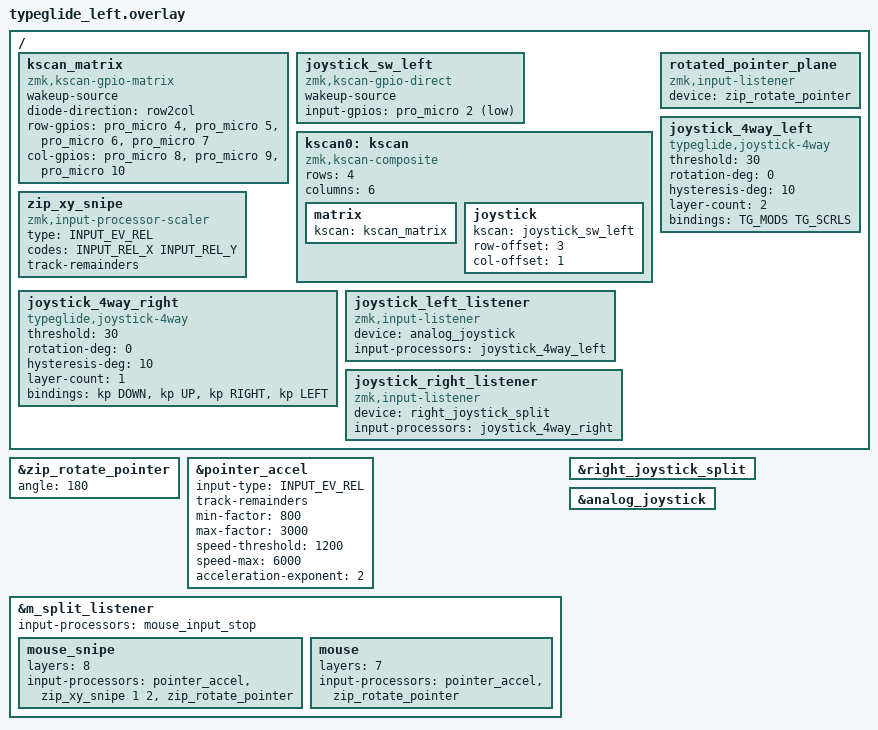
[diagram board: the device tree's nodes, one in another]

#include "typeglide.dtsi"
#include "joystick.dtsi"

#include <dt-bindings/gpio/gpio.h>
#include <input/processors/rotate_plane.dtsi>
#include <input_processor_stop.dtsi>
#include <behaviors/mouse_scroll.dtsi>
#include <dt-bindings/zmk/pointing.h>
#include <input/processors.dtsi>
#include <behaviors/input_gestures_accel.dtsi>
#include <keymap_defs.dtsi>

/*
 * Left half
 *
 * col 0 = ring (outermost)
 * col 1 = middle
 * col 2 = index (innermost)
 *
 * row 3 col 0 = pinky
 * row 3 col 2 = thumb
 * row 3 col 1 = spare
 */

 / {
    kscan_matrix: kscan_matrix {
        compatible = "zmk,kscan-gpio-matrix";
        wakeup-source;
        diode-direction = "row2col";

        row-gpios
            = <&pro_micro 4 GPIO_ACTIVE_HIGH>
            , <&pro_micro 5 GPIO_ACTIVE_HIGH>
            , <&pro_micro 6 GPIO_ACTIVE_HIGH>
            , <&pro_micro 7 GPIO_ACTIVE_HIGH>
            ;

        col-gpios
            = <&pro_micro 8  (GPIO_ACTIVE_HIGH | GPIO_PULL_DOWN)>
            , <&pro_micro 9  (GPIO_ACTIVE_HIGH | GPIO_PULL_DOWN)>
            , <&pro_micro 10 (GPIO_ACTIVE_HIGH | GPIO_PULL_DOWN)>
            ;
    };

    joystick_sw_left: joystick_sw_left {
            compatible = "zmk,kscan-gpio-direct";
            wakeup-source;

            input-gpios =
                <&pro_micro 2 (GPIO_ACTIVE_LOW | GPIO_PULL_UP)>;
    };

    kscan0: kscan {
        compatible = "zmk,kscan-composite";
    //    wakeup-source;

        rows = <4>;
        columns = <6>;

        matrix {
            kscan = <&kscan_matrix>;
        };

        joystick {
            kscan = <&joystick_sw_left>;
            row-offset = <3>;
            col-offset = <1>;
        };
    };

};


/*
 * Rotate the pointing device for the left half.
 */

&zip_rotate_pointer {
    angle = <180>;
};


/*
 * Split pointing input.
 *
 * This is the PMW3610 coming from the right half.
 */

&pointer_accel {
    input-type = <INPUT_EV_REL>;
    track-remainders;

    min-factor = <800>;
    max-factor = <3000>;

    speed-threshold = <1200>;
    speed-max = <6000>;

    acceleration-exponent = <2>;
};

/ {
    zip_xy_snipe: zip_xy_snipe {
        compatible = "zmk,input-processor-scaler";
        #input-processor-cells = <2>;
        type = <INPUT_EV_REL>;
        codes = <INPUT_REL_X INPUT_REL_Y>;
        track-remainders;
    };
};

&m_split_listener {
    status = "okay";
    //status = "disabled";
    input-processors = <&mouse_input_stop>;

    mouse_snipe {
        layers = <8>; // MO_SNIPE_L
        input-processors = <
            &pointer_accel
            &zip_xy_snipe 1 2
            &zip_rotate_pointer

        >;
    };
    mouse  {
        layers = <7>;  // MO_L
        input-processors = <
            &pointer_accel
            &zip_rotate_pointer
        >;
    };


};


/ {
    rotated_pointer_plane {
        compatible = "zmk,input-listener";
        device = <&zip_rotate_pointer>;
    };
};

//      Joystick:                  up
//         screen  <=   forward         backward
//                                down
//
//         bind order: down up forward backward



#define TG_MODS &kp LGUI &kp LCTRL &kp LSHIFT &kp LALT
#define TG_SCRLS &msc SCRL_DOWN &msc SCRL_UP &msc SCRL_LEFT &msc SCRL_RIGHT


/ {
    joystick_4way_left: joystick_4way_left {
        compatible = "typeglide,joystick-4way";
        #input-processor-cells = <0>;

        status = "okay";

        threshold = <30>;
        rotation-deg = <0>;
        hysteresis-deg = <10>;

        layer-count = <2>;

// FWD, BACK, UP,DOWN
        bindings = <
            TG_MODS
            TG_SCRLS
        >;
    };

    joystick_4way_right: joystick_4way_right {
        compatible = "typeglide,joystick-4way";
        #input-processor-cells = <0>;

        status = "okay";

        threshold = <30>;
        rotation-deg = <0>;
        hysteresis-deg = <10>;

        layer-count = <1>;

        bindings = <
             &kp DOWN
             &kp UP
             &kp RIGHT
             &kp LEFT



        >;
    };
};

/ {
    joystick_left_listener {
        compatible = "zmk,input-listener";
        device = <&analog_joystick>;
        input-processors = <&joystick_4way_left>;
    };
};

/ {
    joystick_right_listener {
        compatible = "zmk,input-listener";
        device = <&right_joystick_split>;
        input-processors = <&joystick_4way_right>;
    };
};

&right_joystick_split {
    status = "okay";
    /delete-property/ device;
};


&analog_joystick {
    //status = "disabled";
    status = "okay";
};


/ {
    joystick_left_listener {
      //  status = "disabled";
        status = "okay";
    };
};

&joystick_4way_left {
    status = "okay";
};



/*
 * Local joystick.
 *
 * The left half is central, so its joystick is processed locally.
 *
 * &joystick is ONE analog input device containing:
 *
 *     INPUT_ABS_X
 *     INPUT_ABS_Y
 *
 * The Typeglide processor keeps the X/Y state and converts it
 * into one of:
 *
 *     RIGHT
 *     LEFT
 *     DOWN
 *     UP
 */

/*

 / {



     joystick_4way_left: joystick_4way_left {
        compatible = "typeglide,joystick-4way";

        #input-processor-cells = <0>;

//status = "disabled";

        threshold = <20>;

        layer-count = <2>;

        // DOWN UP FWD BACK
        bindings = <
            // Layer 0: navigation
            &kp DOWN
            &kp UP
            &kp RIGHT
            &kp LEFT

            //* Layer 1: WASD
            &kp W
            &kp S
            &kp A
            &kp D
        >;
    };

    joystick_4way_right: joystick_4way_right {
        compatible = "typeglide,joystick-4way";

        #input-processor-cells = <0>;

//status = "disabled";

        threshold = <20>;

        layer-count = <2>;

        // DOWN UP FWD BACK
        bindings = <
            // Layer 0: navigation
            &kp DOWN
            &kp UP
            &kp RIGHT
            &kp LEFT

            // Layer 1: WASD
            &kp W
            &kp S
            &kp A
            &kp D
        >;
    };
};

 / {
    joystick_listener {
        compatible = "zmk,input-listener";
        device = <&joystick>;
        input-processors = <&joystick_4way_left>;
    };
};

*/


/*
 * Right-half joystick split transport.
 *
 * The right peripheral sends the COMPLETE joystick device
 * (both X and Y events) through one input-split device.
 *
 * reg 0 = PMW3610
 * reg 1 = joystick
 */


/*
 / {




    right_joystick_listener {
         compatible = "zmk,input-listener";
         device = <&right_joystick_split>;
        input-processors = <&joystick_4way_right>;
    };

};
*/
